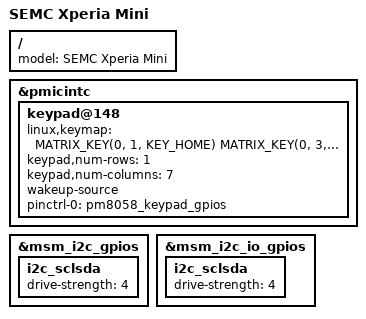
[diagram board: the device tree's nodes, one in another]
#include "qcom-msm7x30-semc-mogami.dtsi"

#include <dt-bindings/input/input.h>

/ {
	model = "SEMC Xperia Mini";
};

&pmicintc {
	keypad@148 {
		linux,keymap = <
			MATRIX_KEY(0, 1, KEY_HOME)
			MATRIX_KEY(0, 3, KEY_VOLUMEUP)
			MATRIX_KEY(0, 4, KEY_VOLUMEDOWN)
			MATRIX_KEY(0, 5, KEY_CAMERA_FOCUS)
			MATRIX_KEY(0, 6, KEY_CAMERA)
			>;
		keypad,num-rows = <1>;
		keypad,num-columns = <7>;
		wakeup-source;

		pinctrl-names = "default";
		pinctrl-0 = <&pm8058_keypad_gpios>;
	};
};

&msm_i2c_gpios {
	i2c_sclsda {
		drive-strength = <4>;
	};
};

&msm_i2c_io_gpios {
	i2c_sclsda {
		drive-strength = <4>;
	};
};
